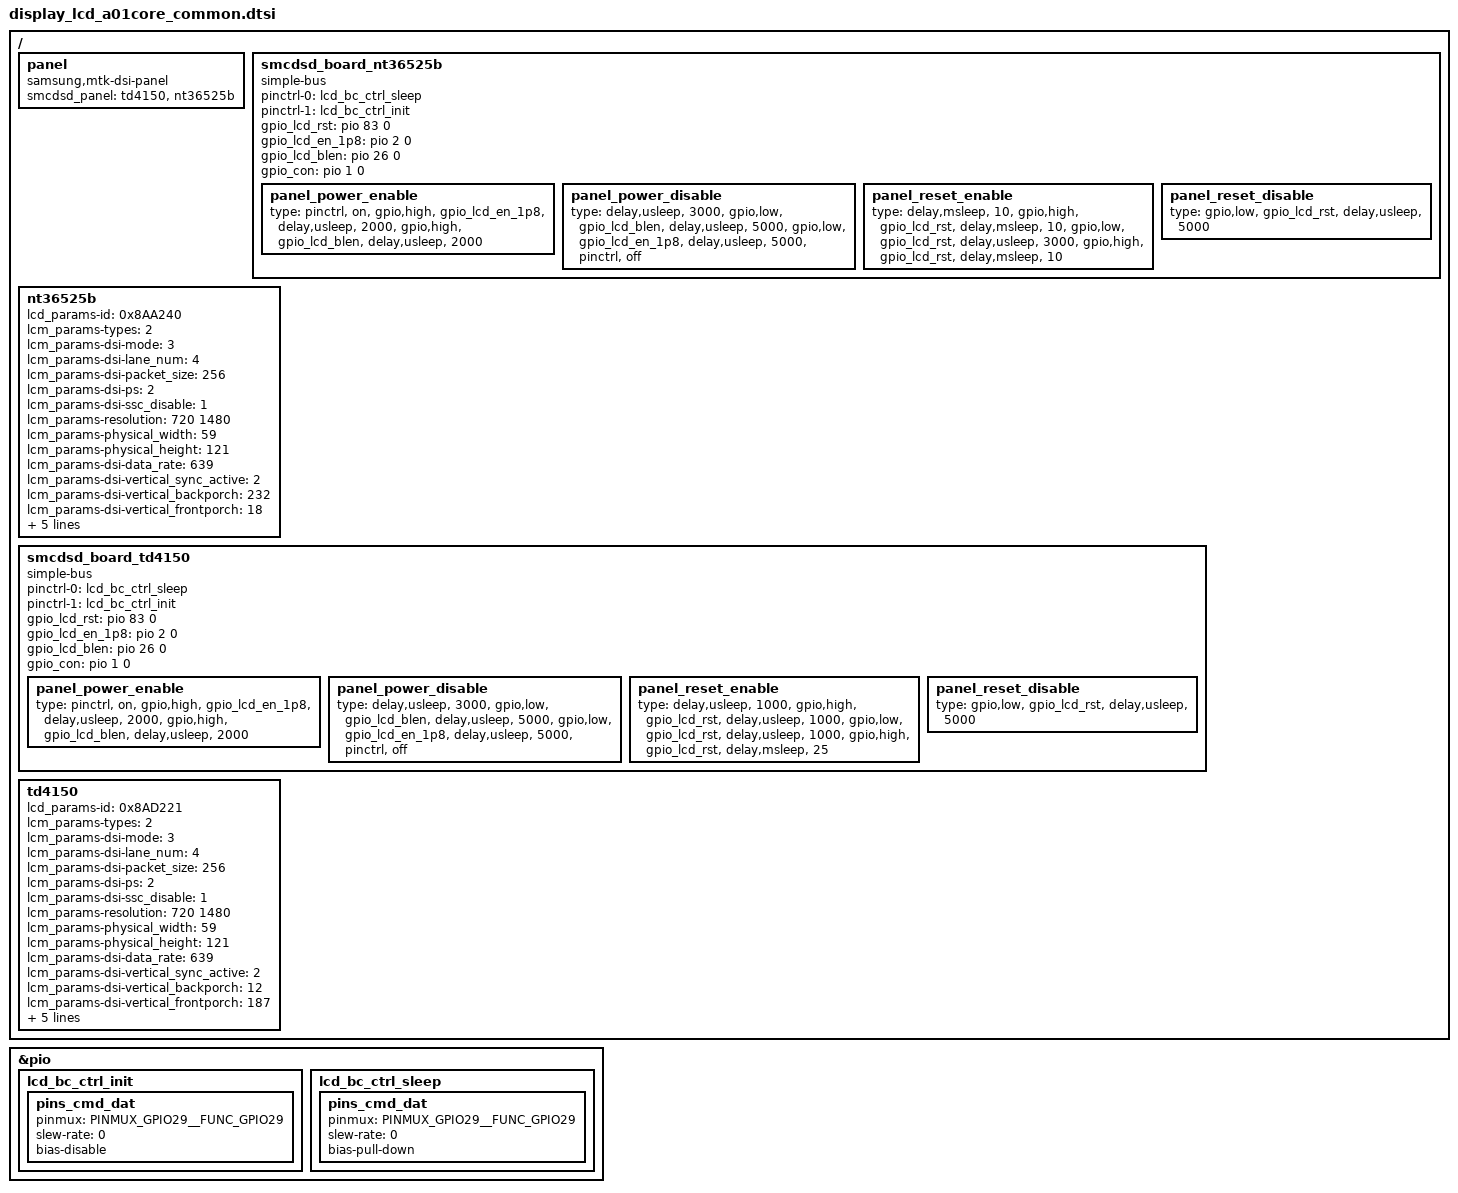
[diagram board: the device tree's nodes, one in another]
/*
 * SAMSUNG LCD Panel Device Tree Source
 *
 * Copyright (c) Samsung Electronics Co., Ltd.
 *		http://www.samsung.com
 *
 * This program is free software; you can redistribute it and/or modify
 * it under the terms of the GNU General Public License version 2 as
 * published by the Free Software Foundation.
 */

&pio {
	lcd_bc_ctrl_init: lcd_bc_ctrl_init {
		pins_cmd_dat {
			pinmux = <PINMUX_GPIO29__FUNC_GPIO29>;
			slew-rate = <0>;
			bias-disable;
		};
	};
	lcd_bc_ctrl_sleep: lcd_bc_ctrl_sleep {
		pins_cmd_dat {
			pinmux = <PINMUX_GPIO29__FUNC_GPIO29>;
			slew-rate = <0>;
			bias-pull-down;
		};
	};

};

/ {
	fragment@lcd {
		target-path = "/";
		__overlay__ {
			panel {
				compatible = "samsung,mtk-dsi-panel";
				smcdsd_panel = <&td4150>,<&nt36525b>; /* default panel at 0th index for pba booting*/
			};

			smcdsd_board_nt36525b: smcdsd_board_nt36525b {
				compatible = "simple-bus";
				pinctrl-names = "off", "on";
				pinctrl-0 = <&lcd_bc_ctrl_sleep>;
				pinctrl-1 = <&lcd_bc_ctrl_init>;

				gpio_lcd_rst = <&pio 83 0>;	/* LCM_RST */
				gpio_lcd_en_1p8 = <&pio 2 0>;	/* LCD_EN_1P8 */
				gpio_lcd_blen = <&pio 26 0>;	/* LCD_BL_EN */
				gpio_con = <&pio 1 0>;	/* LCD_DET */

				panel_power_enable {
					type =
					"pinctrl",		"on",
					"gpio,high",	"gpio_lcd_en_1p8",
					"delay,usleep",	"2000",
					"gpio,high",	"gpio_lcd_blen",
					"delay,usleep",	"2000";
				};
				panel_power_disable {
					type =
					"delay,usleep",	"3000",
					"gpio,low",	"gpio_lcd_blen",
					"delay,usleep",	"5000",
					"gpio,low",	"gpio_lcd_en_1p8",
					"delay,usleep",	"5000",
					"pinctrl",		"off";
				};
				panel_reset_enable {
					type =
					"delay,msleep",	"10",
					"gpio,high",	"gpio_lcd_rst",
					"delay,msleep",	"10",
					"gpio,low",	"gpio_lcd_rst",
					"delay,usleep",	"3000",
					"gpio,high",	"gpio_lcd_rst",
					"delay,msleep",	"10";
				};
				panel_reset_disable {
					type =
					"gpio,low",	"gpio_lcd_rst",
					"delay,usleep",	"5000";
				};
			};

			nt36525b: nt36525b {
				lcd_params-id = <0x8AA240>;
				lcm_params-types = <2>; /* 0: LCM_TYPE_DBI, 1: LCM_TYPE_DPI, 2: LCM_TYPE_DSI */
				lcm_params-dsi-mode = <3>;	/* 0: CMD, 1: SYNC_PULSE_VDO, 2: SYNC_EVENT_VDO, 3: BURST_VDO */
				lcm_params-dsi-lane_num = <4>;
				lcm_params-dsi-packet_size = <256>;
				lcm_params-dsi-ps = <2>; /* 2: LCM_PACKED_PS_24BIT_RGB888 */
				lcm_params-dsi-ssc_disable = <1>;
				lcm_params-resolution = <720 1480>;
				lcm_params-physical_width = <59>;		/* 58.968 mm x 121.212 mm */
				lcm_params-physical_height = <121>;

				lcm_params-dsi-data_rate = <639>;
				lcm_params-dsi-vertical_sync_active = <2>;
				lcm_params-dsi-vertical_backporch = <232>;
				lcm_params-dsi-vertical_frontporch = <18>;
				lcm_params-dsi-horizontal_sync_active = <20>;
				lcm_params-dsi-horizontal_backporch = <107>;
				lcm_params-dsi-horizontal_frontporch = <125>;
				lcm_params-dsi-cont_clock = <1>;

				smcdsd_board = <&smcdsd_board_nt36525b>;
			};
			smcdsd_board_td4150: smcdsd_board_td4150 {
				compatible = "simple-bus";
				pinctrl-names = "off", "on";
				pinctrl-0 = <&lcd_bc_ctrl_sleep>;
				pinctrl-1 = <&lcd_bc_ctrl_init>;

				gpio_lcd_rst = <&pio 83 0>;	/* LCM_RST */
				gpio_lcd_en_1p8 = <&pio 2 0>;	/* LCD_EN_1P8 */
				gpio_lcd_blen = <&pio 26 0>;	/* LCD_BL_EN */
				gpio_con = <&pio 1 0>;	/* LCD_DET */

				panel_power_enable {
					type =
					"pinctrl",		"on",
					"gpio,high",	"gpio_lcd_en_1p8",
					"delay,usleep",	"2000",
					"gpio,high",	"gpio_lcd_blen",
					"delay,usleep",	"2000";
				};
				panel_power_disable {
					type =
					"delay,usleep",	"3000",
					"gpio,low",	"gpio_lcd_blen",
					"delay,usleep",	"5000",
					"gpio,low",	"gpio_lcd_en_1p8",
					"delay,usleep",	"5000",
					"pinctrl",		"off";
				};
				panel_reset_enable {
					type =
					"delay,usleep",	"1000",
					"gpio,high",	"gpio_lcd_rst",
					"delay,usleep",	"1000",
					"gpio,low",	"gpio_lcd_rst",
					"delay,usleep",	"1000",
					"gpio,high",	"gpio_lcd_rst",
					"delay,msleep",	"25";
				};
				panel_reset_disable {
					type =
					"gpio,low",	"gpio_lcd_rst",
					"delay,usleep",	"5000";
				};
			};

			td4150: td4150 {
				lcd_params-id = <0x8AD221>;
				lcm_params-types = <2>; /* 0: LCM_TYPE_DBI, 1: LCM_TYPE_DPI, 2: LCM_TYPE_DSI */
				lcm_params-dsi-mode = <3>;	/* 0: CMD, 1: SYNC_PULSE_VDO, 2: SYNC_EVENT_VDO, 3: BURST_VDO */
				lcm_params-dsi-lane_num = <4>;
				lcm_params-dsi-packet_size = <256>;
				lcm_params-dsi-ps = <2>; /* 2: LCM_PACKED_PS_24BIT_RGB888 */
				lcm_params-dsi-ssc_disable = <1>;
				lcm_params-resolution = <720 1480>;
				lcm_params-physical_width = <59>;		/* 58.968 mm x 121.212 mm */
				lcm_params-physical_height = <121>;

				lcm_params-dsi-data_rate = <639>;
				lcm_params-dsi-vertical_sync_active = <2>;
				lcm_params-dsi-vertical_backporch = <12>;
				lcm_params-dsi-vertical_frontporch = <187>;
				lcm_params-dsi-horizontal_sync_active = <2>;
				lcm_params-dsi-horizontal_backporch = <80>;
				lcm_params-dsi-horizontal_frontporch = <204>;
				lcm_params-dsi-cont_clock = <1>;

				smcdsd_board = <&smcdsd_board_td4150>;
			};
		};
	};
};

/delete-node/ &led6;
